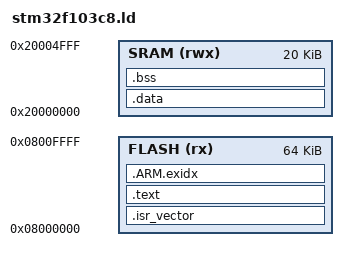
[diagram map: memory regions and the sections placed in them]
ENTRY(Reset_Handler)

MEMORY
{
    FLASH (rx)  : ORIGIN = 0x08000000, LENGTH = 64K
    SRAM  (rwx) : ORIGIN = 0x20000000, LENGTH = 20K
}

PROVIDE(_stack_top = ORIGIN(SRAM) + LENGTH(SRAM));

SECTIONS
{
    .isr_vector :
    {
        . = ALIGN(4);
        KEEP(*(.isr_vector))
        . = ALIGN(4);
    } > FLASH

    .text :
    {
        . = ALIGN(4);
        *(.text*)
        *(.rodata*)
        *(.glue_7)
        *(.glue_7t)
        *(.eh_frame*)
        . = ALIGN(4);
    } > FLASH

    .ARM.exidx :
    {
        . = ALIGN(4);
        *(.ARM.exidx*)
        . = ALIGN(4);
    } > FLASH

    _etext = .;

    _sidata = LOADADDR(.data);

    .data : AT (_etext)
    {
        . = ALIGN(4);
        _sdata = .;
        *(.data*)
        . = ALIGN(4);
        _edata = .;
    } > SRAM

    .bss (NOLOAD) :
    {
        . = ALIGN(4);
        _sbss = .;
        *(.bss*)
        *(COMMON)
        . = ALIGN(4);
        _ebss = .;
    } > SRAM
}
